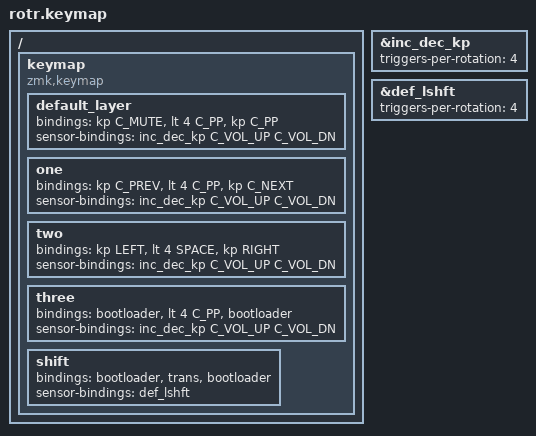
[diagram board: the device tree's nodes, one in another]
#include <behaviors.dtsi>
#include <dt-bindings/zmk/keys.h>
#include <dt-bindings/zmk/rgb.h>
#include <dt-bindings/zmk/bt.h>

&inc_dec_kp {
	triggers-per-rotation = <4>;
};
&def_lshft {
	triggers-per-rotation = <4>;
};

/ {
	keymap {
		compatible = "zmk,keymap";

		default_layer {
			bindings = <&kp C_MUTE &lt 4 C_PP &kp C_PP>;
			sensor-bindings = <&inc_dec_kp C_VOL_UP C_VOL_DN>;
		};
		one {
			bindings = <&kp C_PREV &lt 4 C_PP &kp C_NEXT>;
			sensor-bindings = <&inc_dec_kp C_VOL_UP C_VOL_DN>;
		};
		two {
			bindings = <&kp LEFT &lt 4 SPACE &kp RIGHT>;
			sensor-bindings = <&inc_dec_kp C_VOL_UP C_VOL_DN>;
		};
		three {
			bindings = <&bootloader &lt 4 C_PP &bootloader>;
			sensor-bindings = <&inc_dec_kp C_VOL_UP C_VOL_DN>;
		};
		shift {
			bindings = <&bootloader &trans &bootloader>;
			sensor-bindings = <&def_lshft>;
		};
	};
};
